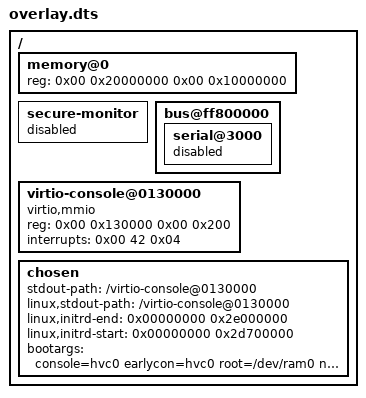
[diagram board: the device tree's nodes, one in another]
/*
 * Copyright 2024, UNSW
 *
 * SPDX-License-Identifier: BSD-2-Clause
 */
/ {
    memory@0 {
        device_type = "memory";
        reg = <0x00 0x20000000 0x00 0x10000000>;
    };



    secure-monitor {
        status = "disabled";
    };

    bus@ff800000 {
        // enable/disable console serial for debugging 
        serial@3000 {
            status = "disabled";
        };
    };

	virtio-console@0130000 {
		compatible = "virtio,mmio";
		reg = <0x00 0x130000 0x00 0x200>;
		interrupts = <0x00 42 0x04>;
	};

    chosen {
        stdout-path = "/virtio-console@0130000";
        linux,stdout-path = "/virtio-console@0130000";
        linux,initrd-end = <0x00000000 0x2e000000>;
        linux,initrd-start = <0x00000000 0x2d700000>;
        bootargs = "console=hvc0 earlycon=hvc0 root=/dev/ram0 nosmp rw debug loglevel=8 pci=nomsi earlyprintk=serial maxcpus=1 uio_pdrv_genirq.of_id=generic-uio";
    };
};
